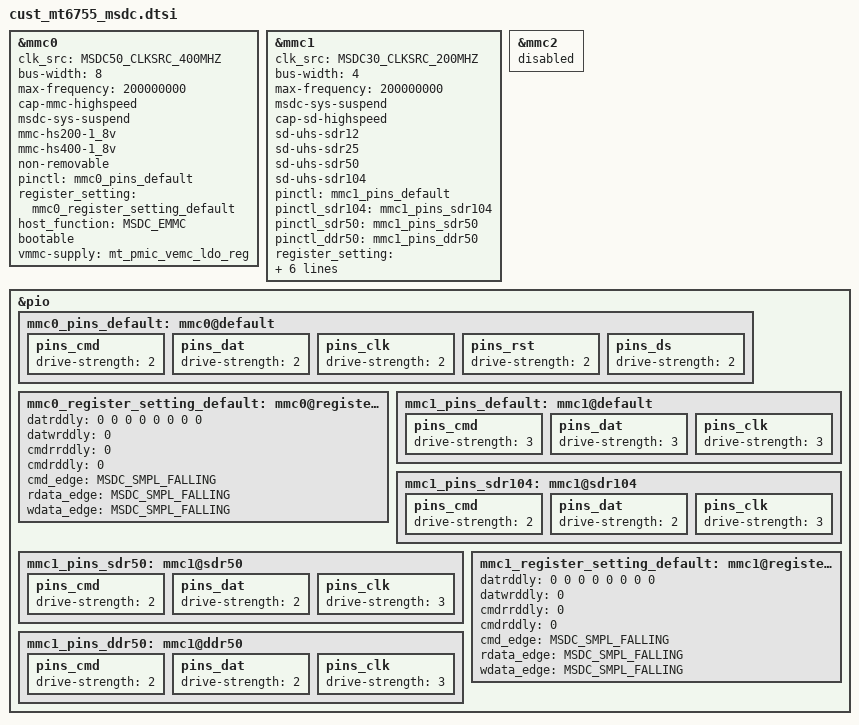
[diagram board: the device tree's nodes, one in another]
/**********************************************
 *MT6755 MSDC DTSI File
********************************************/

&mmc0 {
	clk_src = /bits/ 8 <MSDC50_CLKSRC_400MHZ>;
	bus-width = <8>;
	max-frequency = <200000000>;
	cap-mmc-highspeed;
	msdc-sys-suspend;
	/*mmc-ddr-1_8v;*/
	mmc-hs200-1_8v;
	mmc-hs400-1_8v;
	non-removable;
	pinctl = <&mmc0_pins_default>;
	register_setting = <&mmc0_register_setting_default>;
	host_function = /bits/ 8 <MSDC_EMMC>;
	bootable;
	status = "okay";
	vmmc-supply = <&mt_pmic_vemc_ldo_reg>;
};

&mmc1 {
	clk_src = /bits/ 8 <MSDC30_CLKSRC_200MHZ>;
	bus-width = <4>;
	max-frequency = <200000000>;
	msdc-sys-suspend;
	cap-sd-highspeed;
	sd-uhs-sdr12;
	sd-uhs-sdr25;
	sd-uhs-sdr50;
	sd-uhs-sdr104;
	/*sd-uhs-ddr50;*/
	pinctl = <&mmc1_pins_default>;
	pinctl_sdr104 = <&mmc1_pins_sdr104>;
	pinctl_sdr50 = <&mmc1_pins_sdr50>;
	pinctl_ddr50 = <&mmc1_pins_ddr50>;
	register_setting = <&mmc1_register_setting_default>;
	host_function = /bits/ 8 <MSDC_SD>;
	cd_level = /bits/ 8 <MSDC_CD_LOW>;
	cd-gpios = <&pio 3 0>;
	status = "okay";
	vmmc-supply = <&mt_pmic_vmch_ldo_reg>;
	vqmmc-supply = <&mt_pmic_vmc_ldo_reg>;
};

&mmc2 {
	status = "disable";
};

&pio {
	mmc0_pins_default: mmc0@default {
		pins_cmd {
			drive-strength = /bits/ 8 <2>;
		};
		pins_dat {
			drive-strength = /bits/ 8 <2>;
		};
		pins_clk {
			drive-strength = /bits/ 8 <2>;
		};
		pins_rst {
			drive-strength = /bits/ 8 <2>;
		};
		pins_ds {
			drive-strength = /bits/ 8 <2>;
		};
	};

	mmc0_register_setting_default: mmc0@register_default {
		datrddly      = /bits/ 8 <0 0 0 0 0 0 0 0>;
		datwrddly      = /bits/ 8 <0>;
		cmdrrddly      = /bits/ 8 <0>;
		cmdrddly       = /bits/ 8 <0>;
		cmd_edge = /bits/ 8 <MSDC_SMPL_FALLING>;
		rdata_edge = /bits/ 8 <MSDC_SMPL_FALLING>;
		wdata_edge = /bits/ 8 <MSDC_SMPL_FALLING>;
	};

	mmc1_pins_default: mmc1@default {
		pins_cmd {
			drive-strength = /bits/ 8 <3>;
		};
		pins_dat {
			drive-strength = /bits/ 8 <3>;
		};
		pins_clk {
			drive-strength = /bits/ 8 <3>;
		};
	};

	mmc1_pins_sdr104: mmc1@sdr104 {
		pins_cmd {
			drive-strength = /bits/ 8 <2>;
		};
		pins_dat {
			drive-strength = /bits/ 8 <2>;
		};
		pins_clk {
			drive-strength = /bits/ 8 <3>;
		};
	};

	mmc1_pins_sdr50: mmc1@sdr50 {
		pins_cmd {
			drive-strength = /bits/ 8 <2>;
		};
		pins_dat {
			drive-strength = /bits/ 8 <2>;
		};
		pins_clk {
			drive-strength = /bits/ 8 <3>;
		};
	};

	mmc1_pins_ddr50: mmc1@ddr50 {
		pins_cmd {
			drive-strength = /bits/ 8 <2>;
		};
		pins_dat {
			drive-strength = /bits/ 8 <2>;
		};
		pins_clk {
			drive-strength = /bits/ 8 <3>;
		};
	};

	mmc1_register_setting_default: mmc1@register_default {
		datrddly       = /bits/ 8 <0 0 0 0 0 0 0 0>;
		datwrddly      = /bits/ 8 <0>;
		cmdrrddly      = /bits/ 8 <0>;
		cmdrddly       = /bits/ 8 <0>;
		cmd_edge = /bits/ 8 <MSDC_SMPL_FALLING>;
		rdata_edge = /bits/ 8 <MSDC_SMPL_FALLING>;
		wdata_edge = /bits/ 8 <MSDC_SMPL_FALLING>;
	};
};
